VERSION "Synthetic GT3-style database for the SpatiaX demo. Not a real vehicle; see scripts/synthetic_lap.py."

NS_ :

BS_:

BU_: ECU CHASSIS TPMS LOGGER DASH

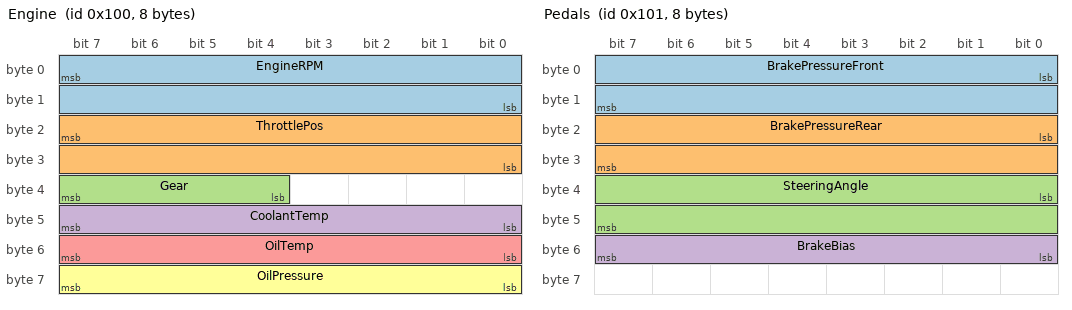
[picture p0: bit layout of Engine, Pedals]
BO_ 256 Engine: 8 ECU
 SG_ EngineRPM : 7|16@0+ (1,0) [0|12000] "rpm" DASH,LOGGER
 SG_ ThrottlePos : 23|16@0+ (0.1,0) [0|100] "%" DASH,LOGGER
 SG_ Gear : 39|4@0+ (1,0) [0|7] "" DASH,LOGGER
 SG_ CoolantTemp : 47|8@0+ (1,-40) [-40|215] "degC" DASH,LOGGER
 SG_ OilTemp : 55|8@0+ (1,-40) [-40|215] "degC" DASH,LOGGER
 SG_ OilPressure : 63|8@0+ (0.05,0) [0|12.75] "bar" DASH,LOGGER

BO_ 257 Pedals: 8 ECU
 SG_ BrakePressureFront : 0|16@1+ (0.1,0) [0|250] "bar" LOGGER
 SG_ BrakePressureRear : 16|16@1+ (0.1,0) [0|250] "bar" LOGGER
 SG_ SteeringAngle : 32|16@1- (0.1,0) [-720|720] "deg" LOGGER
 SG_ BrakeBias : 48|8@1+ (0.5,0) [0|100] "%" DASH,LOGGER

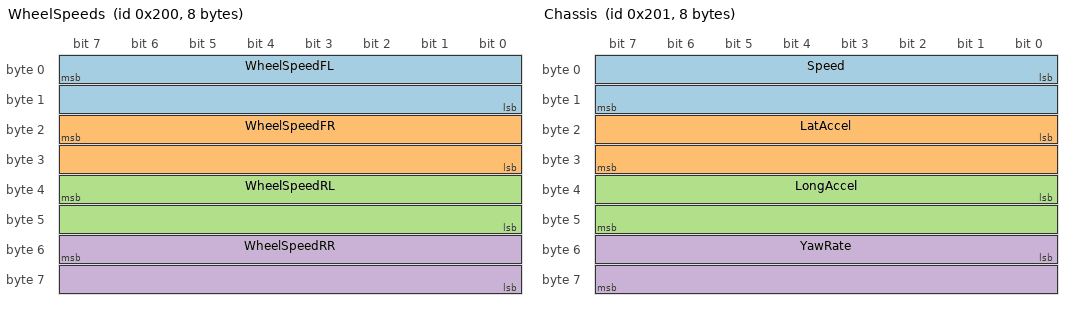
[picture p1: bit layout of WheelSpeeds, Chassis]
BO_ 512 WheelSpeeds: 8 CHASSIS
 SG_ WheelSpeedFL : 7|16@0+ (0.01,0) [0|400] "km/h" LOGGER
 SG_ WheelSpeedFR : 23|16@0+ (0.01,0) [0|400] "km/h" LOGGER
 SG_ WheelSpeedRL : 39|16@0+ (0.01,0) [0|400] "km/h" LOGGER
 SG_ WheelSpeedRR : 55|16@0+ (0.01,0) [0|400] "km/h" LOGGER

BO_ 513 Chassis: 8 CHASSIS
 SG_ Speed : 0|16@1+ (0.01,0) [0|400] "km/h" DASH,LOGGER
 SG_ LatAccel : 16|16@1- (0.001,0) [-4|4] "g" LOGGER
 SG_ LongAccel : 32|16@1- (0.001,0) [-4|4] "g" LOGGER
 SG_ YawRate : 48|16@1- (0.01,0) [-300|300] "deg/s" LOGGER

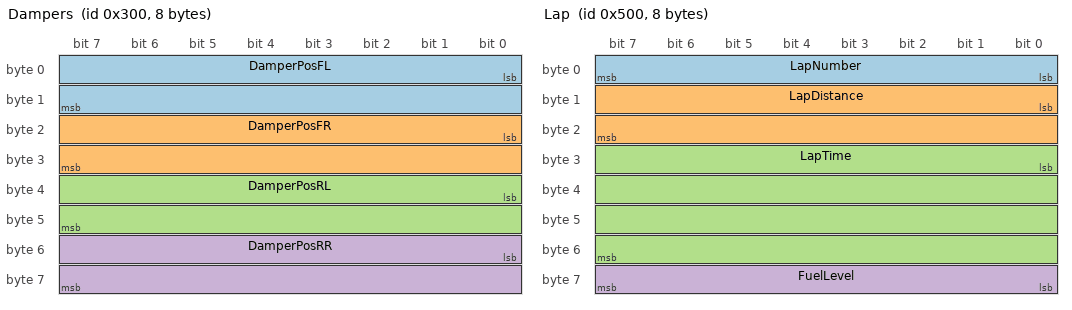
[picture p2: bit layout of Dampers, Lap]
BO_ 768 Dampers: 8 CHASSIS
 SG_ DamperPosFL : 0|16@1- (0.01,0) [-100|100] "mm" LOGGER
 SG_ DamperPosFR : 16|16@1- (0.01,0) [-100|100] "mm" LOGGER
 SG_ DamperPosRL : 32|16@1- (0.01,0) [-100|100] "mm" LOGGER
 SG_ DamperPosRR : 48|16@1- (0.01,0) [-100|100] "mm" LOGGER

BO_ 1024 TyreTemps: 8 TPMS
 SG_ TyreCorner M : 0|8@1+ (1,0) [0|3] "" LOGGER
 SG_ TyreTempInnerFL m0 : 8|16@1+ (0.1,0) [0|200] "degC" LOGGER
 SG_ TyreTempMiddleFL m0 : 24|16@1+ (0.1,0) [0|200] "degC" LOGGER
 SG_ TyreTempOuterFL m0 : 40|16@1+ (0.1,0) [0|200] "degC" LOGGER
 SG_ TyrePressureFL m0 : 56|8@1+ (0.02,0) [0|5.1] "bar" LOGGER
 SG_ TyreTempInnerFR m1 : 8|16@1+ (0.1,0) [0|200] "degC" LOGGER
 SG_ TyreTempMiddleFR m1 : 24|16@1+ (0.1,0) [0|200] "degC" LOGGER
 SG_ TyreTempOuterFR m1 : 40|16@1+ (0.1,0) [0|200] "degC" LOGGER
 SG_ TyrePressureFR m1 : 56|8@1+ (0.02,0) [0|5.1] "bar" LOGGER
 SG_ TyreTempInnerRL m2 : 8|16@1+ (0.1,0) [0|200] "degC" LOGGER
 SG_ TyreTempMiddleRL m2 : 24|16@1+ (0.1,0) [0|200] "degC" LOGGER
 SG_ TyreTempOuterRL m2 : 40|16@1+ (0.1,0) [0|200] "degC" LOGGER
 SG_ TyrePressureRL m2 : 56|8@1+ (0.02,0) [0|5.1] "bar" LOGGER
 SG_ TyreTempInnerRR m3 : 8|16@1+ (0.1,0) [0|200] "degC" LOGGER
 SG_ TyreTempMiddleRR m3 : 24|16@1+ (0.1,0) [0|200] "degC" LOGGER
 SG_ TyreTempOuterRR m3 : 40|16@1+ (0.1,0) [0|200] "degC" LOGGER
 SG_ TyrePressureRR m3 : 56|8@1+ (0.02,0) [0|5.1] "bar" LOGGER

BO_ 1280 Lap: 8 LOGGER
 SG_ LapNumber : 0|8@1+ (1,0) [0|255] "" DASH,LOGGER
 SG_ LapDistance : 8|16@1+ (0.1,0) [0|6553.5] "m" DASH,LOGGER
 SG_ LapTime : 24|32@1+ (0.001,0) [0|4294967.295] "s" DASH,LOGGER
 SG_ FuelLevel : 56|8@1+ (0.5,0) [0|127.5] "l" DASH,LOGGER

CM_ "Synthetic GT3-style database for the SpatiaX demo. The channels, rates, and layouts are plausible for a GT3 car but were invented for the demo; fixtures/demo/synthetic_lap.log is generated from this file by scripts/synthetic_lap.py.";
CM_ BO_ 256 "Engine, 50 Hz.";
CM_ BO_ 257 "Driver inputs, 50 Hz.";
CM_ BO_ 512 "Wheel speeds, 50 Hz.";
CM_ BO_ 513 "Inertial platform, 50 Hz.";
CM_ BO_ 768 "Damper potentiometers, 50 Hz. Positive is compression.";
CM_ BO_ 1024 "Tyre temperatures and pressures, one corner per frame, 5 Hz per corner.";
CM_ BO_ 1280 "Lap timing, 10 Hz.";
BA_DEF_ BO_ "GenMsgCycleTime" INT 0 10000;
BA_DEF_DEF_ "GenMsgCycleTime" 0;
BA_ "GenMsgCycleTime" BO_ 256 20;
BA_ "GenMsgCycleTime" BO_ 257 20;
BA_ "GenMsgCycleTime" BO_ 512 20;
BA_ "GenMsgCycleTime" BO_ 513 20;
BA_ "GenMsgCycleTime" BO_ 768 20;
BA_ "GenMsgCycleTime" BO_ 1024 50;
BA_ "GenMsgCycleTime" BO_ 1280 100;
VAL_ 256 Gear 0 "N" 1 "1st" 2 "2nd" 3 "3rd" 4 "4th" 5 "5th" 6 "6th" 7 "R" ;
VAL_ 1024 TyreCorner 0 "FL" 1 "FR" 2 "RL" 3 "RR" ;
